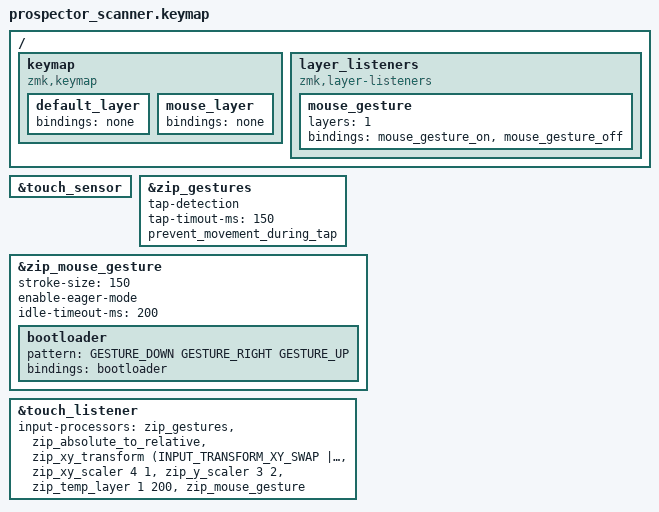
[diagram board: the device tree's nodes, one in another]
/*
 * Copyright (c) 2024 The ZMK Contributors
 *
 * SPDX-License-Identifier: MIT
 */

#include <behaviors.dtsi>
#include <dt-bindings/zmk/keys.h>
#include <dt-bindings/zmk/bt.h>
#include <dt-bindings/zmk/outputs.h>
#include <dt-bindings/zmk/pointing.h>

/ {
    keymap {
        compatible = "zmk,keymap";

        default_layer {
            // Scanner device with minimal input - use none for display-only device
            bindings = <
                &none  // No key action needed for scanner
            >;
        };

        mouse_layer {
            bindings = <
                &none
            >;
        };
    };

    layer_listeners {
        compatible = "zmk,layer-listeners";

        mouse_gesture {
            layers = <1>;
            bindings = <&mouse_gesture_on &mouse_gesture_off>;
        };
    };
};

#include <input/processors.dtsi>
#include <dt-bindings/zmk/input_transform.h>
#include <zephyr/dt-bindings/input/input-event-codes.h>

#include <behaviors/input_processor_gestures.dtsi>
#include <behaviors/input_processor_absolute_to_relative.dtsi>

#include <mouse-gesture.dtsi>

// Alias &touch_sensor to &glidepoint for input gestures module
glidepoint: &touch_sensor {};

&zip_gestures {
    tap-detection;
    tap-timout-ms = <150>;
    prevent_movement_during_tap;
    // inertial-cursor;
};

&zip_mouse_gesture {
    stroke-size = <150>;
    enable-eager-mode;
    idle-timeout-ms = <200>;

    bootloader {
        pattern = <GESTURE_DOWN GESTURE_RIGHT GESTURE_UP>;
        bindings = <&bootloader>;
    };

    // left {
    //     pattern = <GESTURE_LEFT>;
    //     bindings = <&kp LEFT>;
    // };
    // right {
    //     pattern = <GESTURE_RIGHT>;
    //     bindings = <&kp RIGHT>;
    // };
    // up {
    //     pattern = <GESTURE_UP>;
    //     bindings = <&kp UP>;
    // };
    // down {
    //     pattern = <GESTURE_DOWN>;
    //     bindings = <&kp DOWN>;
    // };
};

&touch_listener {
    input-processors = <
        &zip_gestures
        &zip_absolute_to_relative
        &zip_xy_transform (INPUT_TRANSFORM_XY_SWAP | INPUT_TRANSFORM_Y_INVERT)
        &zip_xy_scaler 4 1
        &zip_y_scaler 3 2
        &zip_temp_layer 1 200
        &zip_mouse_gesture
    >;
};
